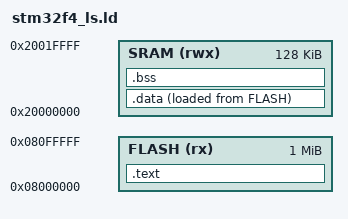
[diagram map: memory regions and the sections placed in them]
ENTRY(Reset_Handler)

MEMORY
{
	FLASH(rx):ORIGIN =0x08000000,LENGTH =1024K
	SRAM(rwx):ORIGIN =0x20000000,LENGTH =128K
}

SECTIONS
{
	.text :
	{
		*(.isr_vector)
		*(.text)
		*(.text*)
		*(.init)
		*(.fini)
		*(.rodata)
		*(.rodata.*)
		. = ALIGN(4);
		_etext = .;
	}> FLASH AT> FLASH

	_lo_data = LOADADDR(.data);

	.data :
	{
		_sdata = .;
		*(.data)
		*(.data.*)
		*(.init_array)
		*(.fini_array)
		. = ALIGN(4);
		_edata = .;
	}> SRAM AT> FLASH

	.bss :
	{
		_sbss = .;
		__bss_start__ = _sbss;
		*(.bss)
		*(.bss.*)
		*(COMMON)
		. = ALIGN(4);
		_ebss = .;
		__bss_end__ = _ebss;
		. = ALIGN(4);
		end = .; 
		__end__ = end;
	}> SRAM AT> SRAM
}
